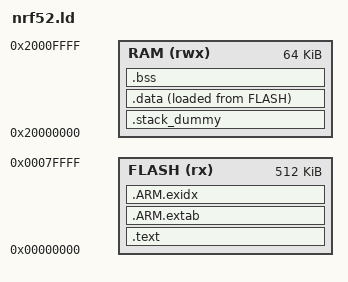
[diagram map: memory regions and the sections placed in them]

SEARCH_DIR(.)
GROUP(-lgcc -lc -lnosys)

MEMORY
{
    FLASH (rx) : ORIGIN = 0x0, LENGTH = 0x80000
    RAM (rwx) :  ORIGIN = 0x20000000, LENGTH = 0x10000
}

__stacksize__ = 0x3000;

SECTIONS
{
    .text :
    {
        KEEP(*(.isr_vector))
        *(.text*)

        KEEP(*(.init))
        KEEP(*(.fini))

        *crtbegin.o(.ctors)
        *crtbegin?.o(.ctors)
        *(EXCLUDE_FILE(*crtend?.o *crtend.o) .ctors)
        *(SORT(.ctors.*))
        *(.ctors)

        *crtbegin.o(.dtors)
        *crtbegin?.o(.dtors)
        *(.dtors)
        *(SORT(.dtors.*))
        *(.dtors)

        *(.rodata*)

        KEEP(*(.eh_frame*))
            __si_data__ = .;
    } > FLASH

    .ARM.extab :
    {
        *(.ARM.extab* .gnu.linkonce.armextab.*)
    } > FLASH

    __exidx_start = .;
    .ARM.exidx :
    {
        *(.ARM.exidx* .gnu.linkonce.armexidx.*)
    } > FLASH
    __exidx_end = .;

    __etext = .;

    .stack_dummy :
    {
        . = . + __stacksize__;
    } > RAM

    .data :
    {
        __data_start__ = .;
        . = ALIGN(4);
        *(.data *data*)
        __data_end__ = .;
    } > RAM AT> FLASH

    .bss :
    {
        . = ALIGN(4);
        __bss_start__ = .;
        *(.bss*)
        . = ALIGN(4);
        __bss_end__ = .;
    } > RAM
}
